# ESP32-S31 register map
Vendor: ESPRESSIF SYSTEMS (SHANGHAI) CO., LTD.; Series: ESP32 S-Series; File version: 1
CPU: RV32IMAFC r0p0, little endian, no MPU, FPU, 0 interrupt priority bits
Address unit: 32 bits
Registers are 32-bit, read-write, reset 0x0 unless marked. A register's access mark holds for its fields unless they carry their own. Offsets are from the block's base; [hi:lo] are bit positions; {n}, {i} and the like mark numbered series.

## LCD_CAM — Camera/LCD Controller
Base 0x20396000
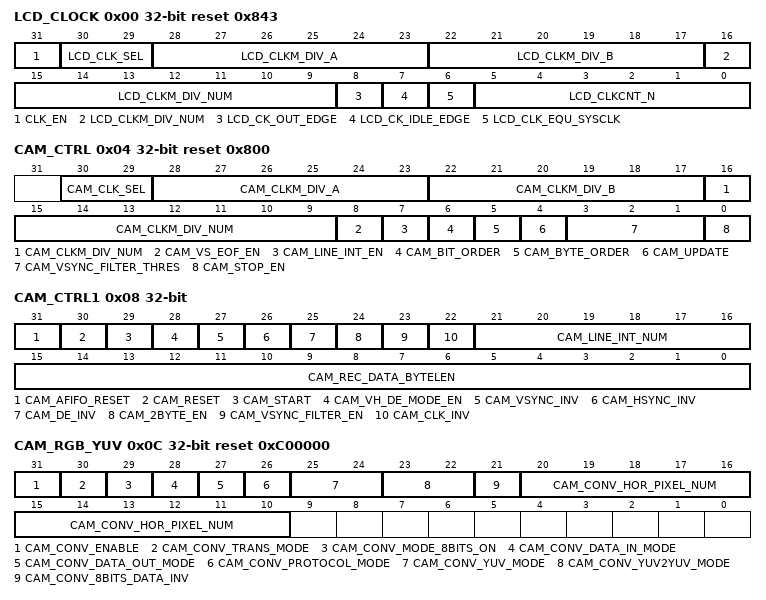
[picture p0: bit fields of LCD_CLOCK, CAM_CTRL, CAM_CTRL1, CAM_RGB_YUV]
0x00 LCD_CLOCK reset 0x843 — LCD clock config register.
  [31] CLK_EN — Set this bit to enable clk gate
  [30:29] LCD_CLK_SEL — Select LCD module source clock. 0: no clock. 1: APLL. 2: CLK160. 3: no clock.
  [28:23] LCD_CLKM_DIV_A — Fractional clock divider denominator value
  [22:17] LCD_CLKM_DIV_B — Fractional clock divider numerator value
  [16:9] LCD_CLKM_DIV_NUM — Integral LCD clock divider value
  [8] LCD_CK_OUT_EDGE — 1: LCD_PCLK line is high in the first half data cycle. 0: LCD_PCLK line is low in the second half data cycle.
  [7] LCD_CK_IDLE_EDGE — 1: LCD_PCLK line is high when idle 0: LCD_PCLK line is low when idle.
  [6] LCD_CLK_EQU_SYSCLK — 1: f_LCD_PCLK = f_LCD_CLK. 0: f_LCD_PCLK = f_LCD_CLK / (reg_clkcnt_N + 1).
  [5:0] LCD_CLKCNT_N — f_LCD_PCLK = f_LCD_CLK / (reg_clkcnt_N + 1) when reg_clk_equ_sysclk is 0.
0x04 CAM_CTRL reset 0x800 — CAM config register.
  [30:29] CAM_CLK_SEL — Select Camera module source clock. 0: no clock. 1: APLL. 2: CLK160. 3: no clock.
  [28:23] CAM_CLKM_DIV_A — Fractional clock divider denominator value
  [22:17] CAM_CLKM_DIV_B — Fractional clock divider numerator value
  [16:9] CAM_CLKM_DIV_NUM — Integral Camera clock divider value
  [8] CAM_VS_EOF_EN — 1: CAM_VSYNC to generate in_suc_eof. 0: in_suc_eof is controlled by reg_cam_rec_data_cyclelen.
  [7] CAM_LINE_INT_EN — 1: Enable to generate CAM_HS_INT. 0: Disable.
  [6] CAM_BIT_ORDER — 1: Change data bit order, change CAM_DATA_in[7:0] to CAM_DATA_in[0:7] in one byte mode, and bits[15:0] to bits[0:15] in two byte mode. 0: Not change.
  [5] CAM_BYTE_ORDER — 1: invert data byte order. 0: Not change.
  [4] CAM_UPDATE — 1: Update Camera registers, will be cleared by hardware. 0 : Not care.
  [3:1] CAM_VSYNC_FILTER_THRES — Filter threshold value for CAM_VSYNC signal.
  [0] CAM_STOP_EN — Camera stop enable signal, 1: camera stops when DMA Rx FIFO is full. 0: Not stop.
0x08 CAM_CTRL1 access per field — CAM config register.
  [31] CAM_AFIFO_RESET wo — Camera AFIFO reset signal.
  [30] CAM_RESET wo — Camera module reset signal.
  [29] CAM_START rw — Camera module start signal.
  [28] CAM_VH_DE_MODE_EN rw — 1: Input control signals are CAM_DE CAM_HSYNC and CAM_VSYNC. 0: Input control signals are CAM_DE and CAM_VSYNC.
  [27] CAM_VSYNC_INV rw — CAM_VSYNC invert enable signal, valid in high level.
  [26] CAM_HSYNC_INV rw — CAM_HSYNC invert enable signal, valid in high level.
  [25] CAM_DE_INV rw — CAM_DE invert enable signal, valid in high level.
  [24] CAM_2BYTE_EN rw — 1: The bit number of input data is 9~16. 0: The bit number of input data is 0~8.
  [23] CAM_VSYNC_FILTER_EN rw — 1: Enable CAM_VSYNC filter function. 0: bypass.
  [22] CAM_CLK_INV rw — 1: Invert the input signal CAM_PCLK. 0: Not invert.
  [21:16] CAM_LINE_INT_NUM rw — The line number minus 1 to generate cam_hs_int.
  [15:0] CAM_REC_DATA_BYTELEN rw — Camera receive data byte length minus 1 to set DMA in_suc_eof_int.
0x0C CAM_RGB_YUV reset 0xC00000 — CAM YUV/RGB converter configuration register.
  [31] CAM_CONV_ENABLE — 0: Bypass converter. 1: Enable converter.
  [30] CAM_CONV_TRANS_MODE — 0: YUV to RGB. 1: RGB to YUV.
  [29] CAM_CONV_MODE_8BITS_ON — 0: 16bits mode. 1: 8bits mode.
  [28] CAM_CONV_DATA_IN_MODE — LIMIT or FULL mode of Data in. 0: limit. 1: full
  [27] CAM_CONV_DATA_OUT_MODE — LIMIT or FULL mode of Data out. 0: limit. 1: full
  [26] CAM_CONV_PROTOCOL_MODE — 0:BT601. 1:BT709.
  [25:24] CAM_CONV_YUV_MODE — 0: yuv422. 1: yuv420. 2: yuv411.The format that Data_in should be converted to.
  [23:22] CAM_CONV_YUV2YUV_MODE — 0: to yuv422. 1: to yuv420. 2: to yuv411. 3: disabled. To enable yuv2yuv mode, trans_mode must be set to 1.
  [21] CAM_CONV_8BITS_DATA_INV — 1:invert every two 8bits input data. 2. disabled.
  [20:10] CAM_CONV_HOR_PIXEL_NUM — the horizontal pixel number when rgb trans to yuv420
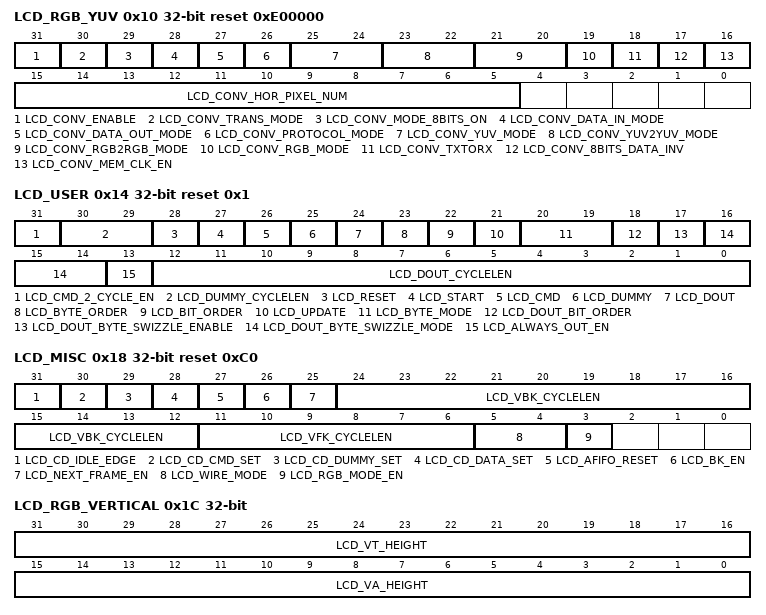
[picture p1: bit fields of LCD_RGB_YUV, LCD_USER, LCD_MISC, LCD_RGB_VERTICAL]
0x10 LCD_RGB_YUV reset 0xE00000 — LCD YUV/RGB converter configuration register.
  [31] LCD_CONV_ENABLE — 0: Bypass converter. 1: Enable converter.
  [30] LCD_CONV_TRANS_MODE — 0: YUV to RGB. 1: RGB to YUV.
  [29] LCD_CONV_MODE_8BITS_ON — 0: 16bits mode. 1: 8bits mode.
  [28] LCD_CONV_DATA_IN_MODE — LIMIT or FULL mode of Data in. 0: limit. 1: full
  [27] LCD_CONV_DATA_OUT_MODE — LIMIT or FULL mode of Data out. 0: limit. 1: full
  [26] LCD_CONV_PROTOCOL_MODE — 0:BT601. 1:BT709.
  [25:24] LCD_CONV_YUV_MODE — 0: yuv422. 1: yuv420. 2: yuv411. When in yuv2yuv mode, yuv_mode decides the yuv mode of Data_in
  [23:22] LCD_CONV_YUV2YUV_MODE — 0: to yuv422. 1: to yuv420. 2: to yuv411. 3: disabled. To enable yuv2yuv mode, trans_mode must be set to 1.
  [21:20] LCD_CONV_RGB2RGB_MODE — 0: to rgb565. 1: to rgb888. Others: disabled.To enable rgb2rgb mode, trans_mode must be set to 0.
  [19] LCD_CONV_RGB_MODE — 0:rgb565.1:rgb888.Determine the rgb format yuv420 trans to.
  [18] LCD_CONV_TXTORX — 0: txtorx mode off. 1: txtorx mode on.
  [17] LCD_CONV_8BITS_DATA_INV — 1:invert every two 8bits input data. 2. disabled.
  [16] LCD_CONV_MEM_CLK_EN — 0:Open the clock gate for lcd convert memory.1: Close the clock gate for lcd convert memory
  [15:5] LCD_CONV_HOR_PIXEL_NUM — the horizontal pixel number when rgb trans to yuv420
0x14 LCD_USER access per field reset 0x1 — LCD config register.
  [31] LCD_CMD_2_CYCLE_EN rw — The cycle length of command phase. 1: 2 cycles. 0: 1 cycle.
  [30:29] LCD_DUMMY_CYCLELEN rw — The dummy cycle length minus 1.
  [28] LCD_RESET wo — The value of command.
  [27] LCD_START rw — LCD start sending data enable signal, valid in high level.
  [26] LCD_CMD rw — 1: Be able to send command in LCD sequence when LCD starts. 0: Disable.
  [25] LCD_DUMMY rw — 1: Enable DUMMY phase in LCD sequence when LCD starts. 0: Disable.
  [24] LCD_DOUT rw — 1: Be able to send data out in LCD sequence when LCD starts. 0: Disable.
  [23] LCD_BYTE_ORDER rw — 1: invert data byte order, only valid in 2 byte mode. 0: Not change.
  [22] LCD_BIT_ORDER rw — 1: Change data bit order, change LCD_DATA_out[7:0] to LCD_DATA_out[0:7] in one byte mode, and bits[15:0] to bits[0:15] in two byte mode. 0: Not change.
  [21] LCD_UPDATE rw — 1: Update LCD registers, will be cleared by hardware. 0 : Not care.
  [20:19] LCD_BYTE_MODE rw — 2: 24bit mode. 1: 16bit mode. 0: 8bit mode
  [18] LCD_DOUT_BIT_ORDER rw — 1: change bit order in every byte. 0: Not change.
  [17] LCD_DOUT_BYTE_SWIZZLE_ENABLE rw — 1: enable byte swizzle 0: disable
  [16:14] LCD_DOUT_BYTE_SWIZZLE_MODE rw — 0: ABAB->BABA. 1: ABC->ACB. 2: ABC->BAC. 3: ABC->BCA. 4:ABC->CAB. 5:ABC->CBA
  [13] LCD_ALWAYS_OUT_EN rw — LCD always output when LCD is in LCD_DOUT state, unless reg_lcd_start is cleared or reg_lcd_reset is set.
  [12:0] LCD_DOUT_CYCLELEN rw — The output data cycles minus 1 of LCD module.
0x18 LCD_MISC access per field reset 0xC0 — LCD config register.
  [31] LCD_CD_IDLE_EDGE rw — The default value of LCD_CD.
  [30] LCD_CD_CMD_SET rw — 1: LCD_CD = !reg_cd_idle_edge when lcd_st[2:0] is in LCD_CMD state. 0: LCD_CD = reg_cd_idle_edge.
  [29] LCD_CD_DUMMY_SET rw — 1: LCD_CD = !reg_cd_idle_edge when lcd_st[2:0] is in LCD_DUMMY state. 0: LCD_CD = reg_cd_idle_edge.
  [28] LCD_CD_DATA_SET rw — 1: LCD_CD = !reg_cd_idle_edge when lcd_st[2:0] is in LCD_DOUT state. 0: LCD_CD = reg_cd_idle_edge.
  [27] LCD_AFIFO_RESET wo — LCD AFIFO reset signal.
  [26] LCD_BK_EN rw — 1: Enable blank region when LCD sends data out. 0: No blank region.
  [25] LCD_NEXT_FRAME_EN rw — 1: Send the next frame data when the current frame is sent out. 0: LCD stops when the current frame is sent out.
  [24:12] LCD_VBK_CYCLELEN rw — The vertical back blank region cycle length minus 1 in LCD RGB mode, or the hold time cycle length in LCD non-RGB mode.
  [11:6] LCD_VFK_CYCLELEN rw — The setup cycle length minus 1 in LCD non-RGB mode.
  [5:4] LCD_WIRE_MODE rw — The wire width of LCD output. 0: 8bit. 1: 16bit 2: 24bit
  [3] LCD_RGB_MODE_EN rw — 1: Enable LCD RGB mode. 0: Disable LCD RGB mode.
0x1C LCD_RGB_VERTICAL — LCD config register.
  [31:16] LCD_VT_HEIGHT — It is the vertical total height of a frame.
  [15:0] LCD_VA_HEIGHT — It is the vertical active height of a frame.
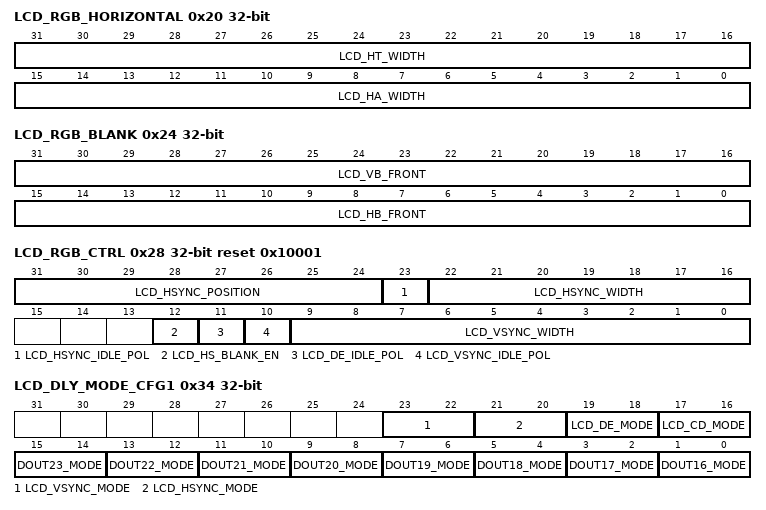
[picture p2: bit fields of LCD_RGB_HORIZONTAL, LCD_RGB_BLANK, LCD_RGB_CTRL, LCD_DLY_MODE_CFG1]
0x20 LCD_RGB_HORIZONTAL — LCD config register.
  [31:16] LCD_HT_WIDTH — It is the horizontal total width of a frame.
  [15:0] LCD_HA_WIDTH — It is the horizontal active width of a frame.
0x24 LCD_RGB_BLANK — LCD config register.
  [31:16] LCD_VB_FRONT — It is the vertical blank front porch of a frame.
  [15:0] LCD_HB_FRONT — It is the horizontal blank front porch of a frame.
0x28 LCD_RGB_CTRL reset 0x10001 — LCD config register.
  [31:24] LCD_HSYNC_POSITION — It is the position of LCD_HSYNC active pulse in a line.
  [23] LCD_HSYNC_IDLE_POL — It is the idle value of LCD_HSYNC.
  [22:16] LCD_HSYNC_WIDTH — It is the position of LCD_HSYNC active pulse in a line.
  [12] LCD_HS_BLANK_EN — 1: The pulse of LCD_HSYNC is out in vertical blanking lines RGB mode. 0: LCD_HSYNC pulse is valid only in active region lines in RGB mode.
  [11] LCD_DE_IDLE_POL — It is the idle value of LCD_DE.
  [10] LCD_VSYNC_IDLE_POL — It is the idle value of LCD_VSYNC.
  [9:0] LCD_VSYNC_WIDTH — It is the position of LCD_VSYNC active pulse in a line.
0x2C LCD_FIRST_CMD_VAL — LCD config register.
  [31:0] LCD_FIRST_CMD_VALUE — The LCD write command value of first cmd cycle.
0x30 LCD_LATTER_CMD_VAL — LCD config register.
  [31:0] LCD_LATTER_CMD_VALUE — The LCD write command value of latter cmd cycle.
0x34 LCD_DLY_MODE_CFG1 — LCD config register.
  [23:22] LCD_VSYNC_MODE — The output LCD_VSYNC is delayed by module clock LCD_CLK. 0: output without delayed. 1: delay by the positive edge of LCD_CLK. 2: delay by the negative edge of LCD_CLK.
  [21:20] LCD_HSYNC_MODE — The output LCD_HSYNC is delayed by module clock LCD_CLK. 0: output without delayed. 1: delay by the positive edge of LCD_CLK. 2: delay by the negative edge of LCD_CLK.
  [19:18] LCD_DE_MODE — The output LCD_DE is delayed by module clock LCD_CLK. 0: output without delayed. 1: delay by the positive edge of LCD_CLK. 2: delay by the negative edge of LCD_CLK.
  [17:16] LCD_CD_MODE — The output LCD_CD is delayed by module clock LCD_CLK. 0: output without delayed. 1: delay by the positive edge of LCD_CLK. 2: delay by the negative edge of LCD_CLK.
  [2n-31:2n-32] DOUT{n}_MODE (n=16..23) — The output data bit {2n-32} is delayed by module clock LCD_CLK. 0: output without delayed. 1: delay by the positive edge of LCD_CLK. 2: delay by the negative edge of LCD_CLK.
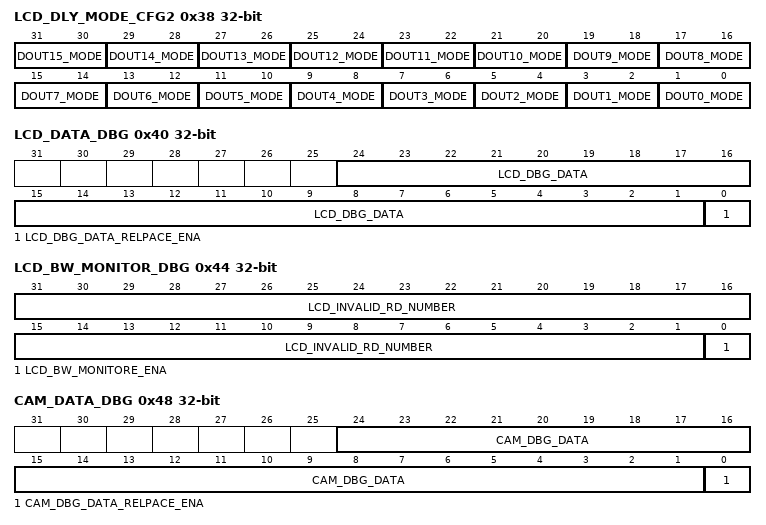
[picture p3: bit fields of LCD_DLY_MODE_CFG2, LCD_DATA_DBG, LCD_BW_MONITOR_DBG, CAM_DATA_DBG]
0x38 LCD_DLY_MODE_CFG2 — LCD config register.
  [2n+1:2n] DOUT{n}_MODE (n=0..15) — The output data bit {2n} is delayed by module clock LCD_CLK. 0: output without delayed. 1: delay by the positive edge of LCD_CLK. 2: delay by the negative edge of LCD_CLK.
0x3C LCD_TRANS_BUFF_CFG — LCD trans buffer register
  [0] LCD_TRANS_BUFFER_ENA — 1:enable lcd trans buffer.0:not enable lcd trans buffer
0x40 LCD_DATA_DBG — LCDCAM LCD debug data register
  [24:1] LCD_DBG_DATA — the debug data that used to replace data read from dma
  [0] LCD_DBG_DATA_RELPACE_ENA — 1:replace the data read from dma.0:not replace the data read from dma
0x44 LCD_BW_MONITOR_DBG access per field — LCDCAM LCD monitor bandwidth debug register
  [31:1] LCD_INVALID_RD_NUMBER ro — the statistical data that lcd rd invalid data
  [0] LCD_BW_MONITORE_ENA rw — 1:enable lcd monitor bandwidth.0: not enable lcd monitor bandwidth
0x48 CAM_DATA_DBG — LCDCAM CAM debug data register
  [24:1] CAM_DBG_DATA — the debug data that used to replace data write to dma
  [0] CAM_DBG_DATA_RELPACE_ENA — 1:replace the data write to dma.0:not replace the data write to dma
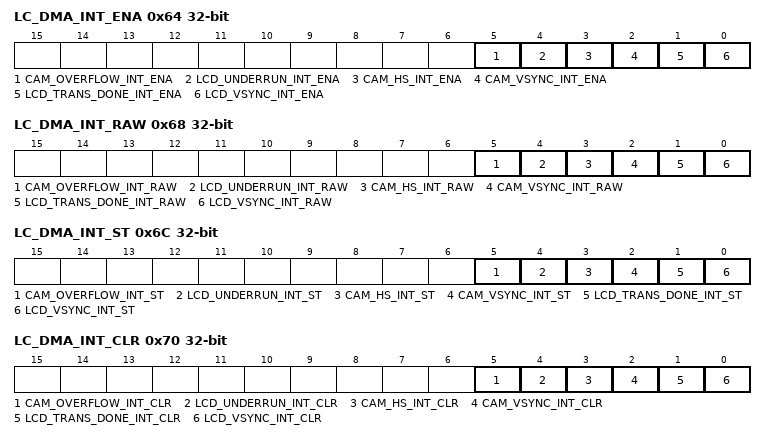
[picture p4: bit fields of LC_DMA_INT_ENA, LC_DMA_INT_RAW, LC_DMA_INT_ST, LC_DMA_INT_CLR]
0x64 LC_DMA_INT_ENA — LCDCAM interrupt enable register.
  [5] CAM_OVERFLOW_INT_ENA — The enable bit for Camera overflow interrupt
  [4] LCD_UNDERRUN_INT_ENA — The enable bit for LCD underrun interrupt
  [3] CAM_HS_INT_ENA — The enable bit for Camera line interrupt.
  [2] CAM_VSYNC_INT_ENA — The enable bit for Camera frame end interrupt.
  [1] LCD_TRANS_DONE_INT_ENA — The enable bit for lcd transfer end interrupt.
  [0] LCD_VSYNC_INT_ENA — The enable bit for LCD frame end interrupt.
0x68 LC_DMA_INT_RAW ro — LCDCAM interrupt raw register, valid in level.
  [5] CAM_OVERFLOW_INT_RAW — The raw bit for Camera overflow interrupt
  [4] LCD_UNDERRUN_INT_RAW — The raw bit for LCD underrun interrupt
  [3] CAM_HS_INT_RAW — The raw bit for Camera line interrupt.
  [2] CAM_VSYNC_INT_RAW — The raw bit for Camera frame end interrupt.
  [1] LCD_TRANS_DONE_INT_RAW — The raw bit for lcd transfer end interrupt.
  [0] LCD_VSYNC_INT_RAW — The raw bit for LCD frame end interrupt.
0x6C LC_DMA_INT_ST ro — LCDCAM interrupt status register.
  [5] CAM_OVERFLOW_INT_ST — The status bit for Camera overflow interrupt
  [4] LCD_UNDERRUN_INT_ST — The status bit for LCD underrun interrupt
  [3] CAM_HS_INT_ST — The status bit for Camera transfer end interrupt.
  [2] CAM_VSYNC_INT_ST — The status bit for Camera frame end interrupt.
  [1] LCD_TRANS_DONE_INT_ST — The status bit for lcd transfer end interrupt.
  [0] LCD_VSYNC_INT_ST — The status bit for LCD frame end interrupt.
0x70 LC_DMA_INT_CLR wo — LCDCAM interrupt clear register.
  [5] CAM_OVERFLOW_INT_CLR — The clear bit for Camera overflow interrupt
  [4] LCD_UNDERRUN_INT_CLR — The clear bit for LCD underrun interrupt
  [3] CAM_HS_INT_CLR — The clear bit for Camera line interrupt.
  [2] CAM_VSYNC_INT_CLR — The clear bit for Camera frame end interrupt.
  [1] LCD_TRANS_DONE_INT_CLR — The clear bit for lcd transfer end interrupt.
  [0] LCD_VSYNC_INT_CLR — The clear bit for LCD frame end interrupt.
0xFC LC_REG_DATE reset 0x2504210 — Version register
  [27:0] LC_DATE — LCD_CAM version control register
